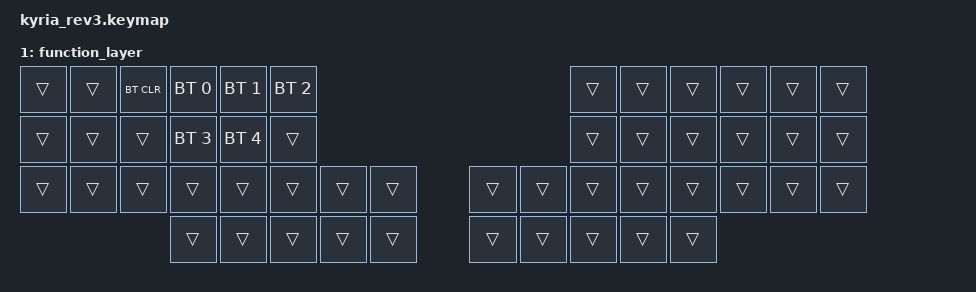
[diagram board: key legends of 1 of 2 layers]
/*
 * Copyright (c) 2023 The ZMK Contributors
 *
 * SPDX-License-Identifier: MIT
 */

#include <behaviors.dtsi>
#include <dt-bindings/zmk/bt.h>
#include <dt-bindings/zmk/keys.h>

/* Uncomment this block if using RGB
&led_strip {
    chain-length = <6>;
    // chain-length = <31>; // Uncomment if using both per-key and underglow LEDs
    // chain-length = <25>; // Uncomment if using only per-key LEDs.
};
 */

/ {
    keymap {
        compatible = "zmk,keymap";

        default_layer {
            // ---------------------------------------------------------------------------------------------------------------------------------
            // |  ESC  |  Q  |  W  |  E   |  R   |  T   |                                          |  Y   |  U    |  I    |  O   |   P   |   \  |
            // |  TAB  |  A  |  S  |  D   |  F   |  G   |                                          |  H   |  J    |  K    |  L   |   ;   |   '  |
            // | SHIFT |  Z  |  X  |  C   |  V   |  B   | L SHIFT | L SHIFT |  | LAYER 1 | L SHIFT |  N   |  M    |  ,    |  .   |   /   | CTRL |
            //                     | GUI  | DEL  | RET  |  SPACE  |   ESC   |  |   RET   |  SPACE  | TAB  | BSPC  | R-ALT |
            bindings = <
            &kp N1  &kp N2  &kp N3  &kp N4  &kp N5                                                  &kp N6 &kp N7  &kp N8    &kp N9  &kp N0
            &kp Q   &kp W   &kp F   &kp P   &kp D                                                   &kp J  &kp L   &kp U     &kp Y   &kp SEMI
            &kp A   &kp R   &kp S   &kp T   &kp G                                                   &kp M  &kp N   &kp N     &kp I   &kp O
            &kp Z   &kp X   &kp C   &kp D   &kp V                                                   &kp K  &kp H   &kp COMMA &kp DOT &kp FSLH
            >;

        };
        function_layer {
            // ---------------------------------------------------------------------------------------------------------------------------------
            // |       |      |BT_CLR|BTSEL0|BTSEL1|BTSEL2|                                         |      |      |      |      |      |      |
            // |       |      |      |BTSEL3|BTSEL4|      |                                         |      |      |      |      |      |      |
            // |       |      |      |      |      |      |      |      |      |      |      |      |      |      |      |      |      |      |
            //                       |      |      |      |      |      |      |      |      |      |      |      |      |
            bindings = <
            &trans &trans &bt BT_CLR &bt BT_SEL 0 &bt BT_SEL 1 &bt BT_SEL 2              &trans &trans &trans &trans &trans &trans
            &trans &trans &trans     &bt BT_SEL 3 &bt BT_SEL 4 &trans                    &trans &trans &trans &trans &trans &trans
            &trans &trans &trans &trans &trans &trans &trans &trans        &trans &trans &trans &trans &trans &trans &trans &trans
                                 &trans &trans &trans &trans &trans        &trans &trans &trans &trans &trans
            >;
        };
    };
};
